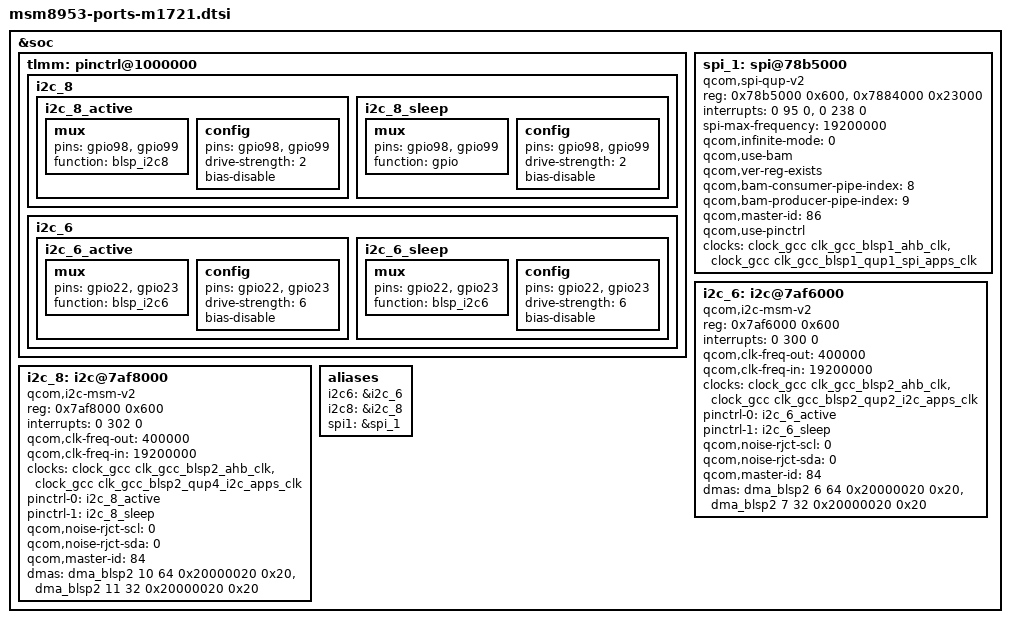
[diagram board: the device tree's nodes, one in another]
/*
 * Copyright (c) 2017, The Linux Foundation. All rights reserved.
 *
 * This program is free software; you can redistribute it and/or modify
 * it under the terms of the GNU General Public License version 2 and
 * only version 2 as published by the Free Software Foundation.
 *
 * This program is distributed in the hope that it will be useful,
 * but WITHOUT ANY WARRANTY; without even the implied warranty of
 * MERCHANTABILITY or FITNESS FOR A PARTICULAR PURPOSE.  See the
 * GNU General Public License for more details.
 */

&soc {
        tlmm: pinctrl@1000000 {
                
                /*
                 * i2c 8 port
                */

                i2c_8 {

                        i2c_8_active: i2c_8_active {

                                mux {
                                        pins = "gpio98", "gpio99";
                                        function = "blsp_i2c8";
                                };

                                config {
                                        pins = "gpio98", "gpio99";
                                        drive-strength = <2>;
                                        bias-disable;
                                };

                        };

                        i2c_8_sleep: i2c_8_sleep {

                                mux {
                                        pins = "gpio98", "gpio99";
                                        function = "gpio";
                                };

                                config {
                                        pins = "gpio98", "gpio99";
                                        drive-strength = <2>;
                                        bias-disable;
                                };

                        };

                };

                /*
                 * i2c 6 port
                */

                i2c_6 {

                        i2c_6_active: i2c_6_active {

                                mux {
                                        pins = "gpio22", "gpio23";
                                        function = "blsp_i2c6";
                                };

                                config {
                                        pins = "gpio22", "gpio23";
                                        drive-strength = <6>;
                                        bias-disable;
                                };

                        };

                        i2c_6_sleep: i2c_6_sleep {

                                mux {
                                        pins = "gpio22", "gpio23";
                                        function = "blsp_i2c6";
                                };

                                config {
                                        pins = "gpio22", "gpio23";
                                        drive-strength = <6>;
                                        bias-disable;
                                };

                        };

                };

        };

        spi_1: spi@78b5000 { /* BLSP1 QUP1 */
                compatible = "qcom,spi-qup-v2";
                reg-names = "spi_physical", "spi_bam_physical";
                reg = <0x78b5000 0x600>, 
                      <0x7884000 0x23000>;
                interrupt-names = "spi_irq", "spi_bam_irq";
                interrupts = <0 95 0>, <0 238 0>;
                spi-max-frequency = <19200000>;
                qcom,infinite-mode = <0>;
                qcom,use-bam;
                qcom,ver-reg-exists;
                qcom,bam-consumer-pipe-index = <8>;
                qcom,bam-producer-pipe-index = <9>;
                qcom,master-id = <86>;
                qcom,use-pinctrl;
                clock-names = "iface_clk", "core_clk";
                clocks = <&clock_gcc clk_gcc_blsp1_ahb_clk>,
                         <&clock_gcc clk_gcc_blsp1_qup1_spi_apps_clk>;
                status = "ok";
        };

        i2c_6: i2c@7af6000 { /* BLSP2 QUP2 */
                compatible = "qcom,i2c-msm-v2";
                reg-names = "qup_phys_addr";
                reg = <0x7af6000 0x600>;
                interrupt-names = "qup_irq";
                interrupts = <0 300 0>;
                qcom,clk-freq-out = <400000>;
                qcom,clk-freq-in = <19200000>;
                clock-names = "iface_clk", "core_clk";
                clocks = <&clock_gcc clk_gcc_blsp2_ahb_clk>,
                         <&clock_gcc clk_gcc_blsp2_qup2_i2c_apps_clk>;
                pinctrl-names = "i2c_active", "i2c_sleep";
                pinctrl-0 = <&i2c_6_active>;
                pinctrl-1 = <&i2c_6_sleep>;
                qcom,noise-rjct-scl = <0>;
                qcom,noise-rjct-sda = <0>;
                qcom,master-id = <84>;
                dmas = <&dma_blsp2 6 64 0x20000020 0x20>, 
                       <&dma_blsp2 7 32 0x20000020 0x20>;
                dma-names = "tx", "rx";
                status = "okay";
        };

        i2c_8: i2c@7af8000 { /* BLSP2 QUP4 */
                compatible = "qcom,i2c-msm-v2";
                reg-names = "qup_phys_addr";
                reg = <0x7af8000 0x600>;
                interrupt-names = "qup_irq";
                interrupts = <0 302 0>;
                qcom,clk-freq-out = <400000>;
                qcom,clk-freq-in = <19200000>;
                clock-names = "iface_clk", "core_clk";
                clocks = <&clock_gcc clk_gcc_blsp2_ahb_clk>, 
                         <&clock_gcc clk_gcc_blsp2_qup4_i2c_apps_clk>;
                pinctrl-names = "i2c_active", "i2c_sleep";
                pinctrl-0 = <&i2c_8_active>;
                pinctrl-1 = <&i2c_8_sleep>;
                qcom,noise-rjct-scl = <0>;
                qcom,noise-rjct-sda = <0>;
                qcom,master-id = <84>;
                dmas = <&dma_blsp2 10 64 0x20000020 0x20>, 
                       <&dma_blsp2 11 32 0x20000020 0x20>;
                dma-names = "tx", "rx";
                status = "ok";
        };

        aliases {
                i2c6 = &i2c_6;
                i2c8 = &i2c_8;
                spi1 = &spi_1;
        };
};

 
